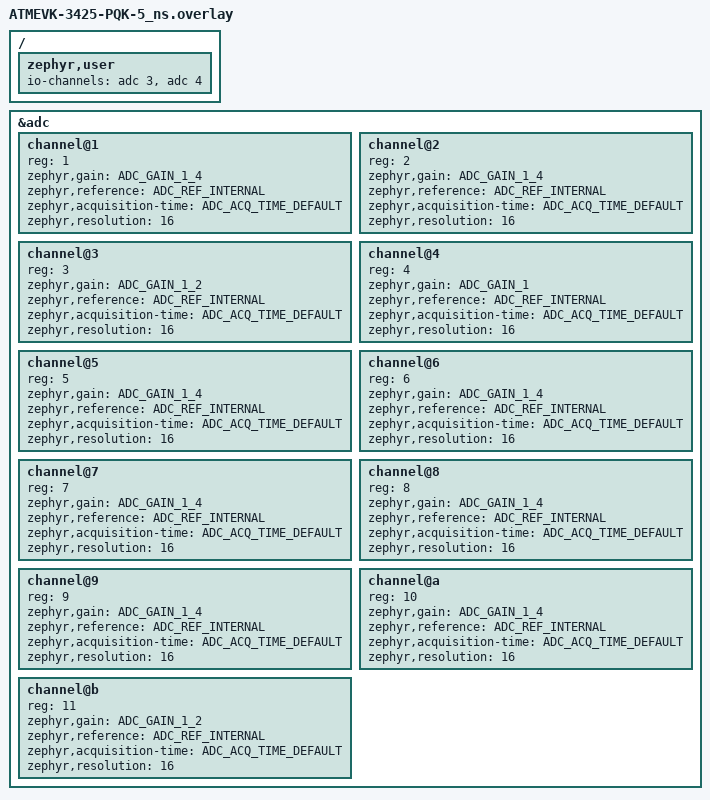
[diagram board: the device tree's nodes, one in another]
/*
 * Copyright (c) 2023 Atmosic
 *
 * SPDX-License-Identifier: Apache-2.0
 */

/ {
	zephyr,user {
		io-channels = <&adc 3>, <&adc 4>;
	};
};

&adc {
	#address-cells = <1>;
	#size-cells = <0>;

	channel@1 {
		reg = <1>;
		zephyr,gain = "ADC_GAIN_1_4";
		zephyr,reference = "ADC_REF_INTERNAL";
		zephyr,acquisition-time = <ADC_ACQ_TIME_DEFAULT>;
		zephyr,resolution = <16>;
	};

	channel@2 {
		reg = <2>;
		zephyr,gain = "ADC_GAIN_1_4";
		zephyr,reference = "ADC_REF_INTERNAL";
		zephyr,acquisition-time = <ADC_ACQ_TIME_DEFAULT>;
		zephyr,resolution = <16>;
	};

	channel@3 {
		reg = <3>;
		zephyr,gain = "ADC_GAIN_1_2";
		zephyr,reference = "ADC_REF_INTERNAL";
		zephyr,acquisition-time = <ADC_ACQ_TIME_DEFAULT>;
		zephyr,resolution = <16>;
	};

	channel@4 {
		reg = <4>;
		zephyr,gain = "ADC_GAIN_1";
		zephyr,reference = "ADC_REF_INTERNAL";
		zephyr,acquisition-time = <ADC_ACQ_TIME_DEFAULT>;
		zephyr,resolution = <16>;
	};

	channel@5 {
		reg = <5>;
		zephyr,gain = "ADC_GAIN_1_4";
		zephyr,reference = "ADC_REF_INTERNAL";
		zephyr,acquisition-time = <ADC_ACQ_TIME_DEFAULT>;
		zephyr,resolution = <16>;
	};

	channel@6 {
		reg = <6>;
		zephyr,gain = "ADC_GAIN_1_4";
		zephyr,reference = "ADC_REF_INTERNAL";
		zephyr,acquisition-time = <ADC_ACQ_TIME_DEFAULT>;
		zephyr,resolution = <16>;
	};

	channel@7 {
		reg = <7>;
		zephyr,gain = "ADC_GAIN_1_4";
		zephyr,reference = "ADC_REF_INTERNAL";
		zephyr,acquisition-time = <ADC_ACQ_TIME_DEFAULT>;
		zephyr,resolution = <16>;
	};

	channel@8 {
		reg = <8>;
		zephyr,gain = "ADC_GAIN_1_4";
		zephyr,reference = "ADC_REF_INTERNAL";
		zephyr,acquisition-time = <ADC_ACQ_TIME_DEFAULT>;
		zephyr,resolution = <16>;
	};

	channel@9 {
		reg = <9>;
		zephyr,gain = "ADC_GAIN_1_4";
		zephyr,reference = "ADC_REF_INTERNAL";
		zephyr,acquisition-time = <ADC_ACQ_TIME_DEFAULT>;
		zephyr,resolution = <16>;
	};

	channel@a {
		reg = <10>;
		zephyr,gain = "ADC_GAIN_1_4";
		zephyr,reference = "ADC_REF_INTERNAL";
		zephyr,acquisition-time = <ADC_ACQ_TIME_DEFAULT>;
		zephyr,resolution = <16>;
	};

	channel@b {
		reg = <11>;
		zephyr,gain = "ADC_GAIN_1_2";
		zephyr,reference = "ADC_REF_INTERNAL";
		zephyr,acquisition-time = <ADC_ACQ_TIME_DEFAULT>;
		zephyr,resolution = <16>;
	};
};
